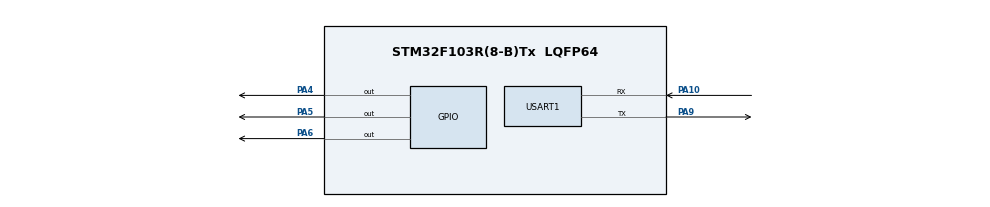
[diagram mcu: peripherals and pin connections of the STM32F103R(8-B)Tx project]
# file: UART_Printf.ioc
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Mcu.Family=STM32F1
Mcu.Name=STM32F103R(8-B)Tx
Mcu.Package=LQFP64
NVIC.PriorityGroup=NVIC_PRIORITYGROUP_2
NVIC.USART1_IRQn=true\:2\:3\:true\:false\:true\:true\:true\:true
PA10.Mode=Asynchronous
PA10.Signal=USART1_RX
PA4.Signal=GPIO_Output
PA5.Signal=GPIO_Output
PA6.Signal=GPIO_Output
PA9.Mode=Asynchronous
PA9.Signal=USART1_TX
ProjectManager.HeapSize=0x200
ProjectManager.StackSize=0x400
ProjectManager.TargetToolchain=CMake
RCC.APB1Freq_Value=8000000
RCC.APB2Freq_Value=8000000
USART1.VirtualMode=VM_ASYNC
VP_SYS_VS_ND.Mode=No_Debug
board=custom

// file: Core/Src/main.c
/* USER CODE BEGIN Header */
/**
  ******************************************************************************
  * @file           : main.c
  * @brief          : Main program body
  ******************************************************************************
  * @attention
  *
  * Copyright (c) 2025 STMicroelectronics.
  * All rights reserved.
  *
  * This software is licensed under terms that can be found in the LICENSE file
  * in the root directory of this software component.
  * If no LICENSE file comes with this software, it is provided AS-IS.
  *
  ******************************************************************************
  */
/* USER CODE END Header */
#include "main.h"
#include "usart.h"
#include "gpio.h"
#include <stdio.h>
#include <string.h>
#include <stdint.h>
#include <stdbool.h>
#include "Unity/unity.h"

/* Test function declarations */
void test_uart_init_should_set_baudrate(void);
void test_uart_transmit_should_return_ok(void);

void SystemClock_Config(void);

/* USER CODE BEGIN 0 */
int __io_putchar(int ch)
{
  HAL_UART_Transmit(&huart1, (uint8_t *)&ch, 1, HAL_MAX_DELAY & 0xFFFF);
  return ch;
}
/* USER CODE END 0 */

int main(void)
{

  /* MCU Configuration--------------------------------------------------------*/

  /* Reset of all peripherals, Initializes the Flash interface and the Systick. */
  HAL_Init();

  /* Configure the system clock */
  SystemClock_Config();

  /* Initialize all configured peripherals */
  MX_GPIO_Init();
  MX_USART1_UART_Init();
  /* USER CODE BEGIN 2 */

  /* Run unit tests */
  printf("\r\n=== Starting UART Tests ===\r\n");
  UNITY_BEGIN();
  RUN_TEST(test_uart_init_should_set_baudrate);
  RUN_TEST(test_uart_transmit_should_return_ok);
  UNITY_END();
  printf("=== UART Tests Complete ===\r\n\r\n");

  /* USER CODE END 2 */

  /* Infinite loop */
  /* USER CODE BEGIN WHILE */
  while (1)
  {
    // static uint8_t cnt = 0;
    /* USER CODE END WHILE */
    // printf("Hello from UART Printf Example %d\r\n", cnt++);
    // HAL_Delay(100);
  }
}

void SystemClock_Config(void)
{
  RCC_OscInitTypeDef RCC_OscInitStruct = {0};
  RCC_ClkInitTypeDef RCC_ClkInitStruct = {0};

  /** Initializes the RCC Oscillators according to the specified parameters
  * in the RCC_OscInitTypeDef structure.
  */
  RCC_OscInitStruct.OscillatorType = RCC_OSCILLATORTYPE_HSI;
  RCC_OscInitStruct.HSIState = RCC_HSI_ON;
  RCC_OscInitStruct.HSICalibrationValue = RCC_HSICALIBRATION_DEFAULT;
  RCC_OscInitStruct.PLL.PLLState = RCC_PLL_NONE;
  if (HAL_RCC_OscConfig(&RCC_OscInitStruct) != HAL_OK)
  {
    Error_Handler();
  }

  /** Initializes the CPU, AHB and APB buses clocks
  */
  RCC_ClkInitStruct.ClockType = RCC_CLOCKTYPE_HCLK|RCC_CLOCKTYPE_SYSCLK
                              |RCC_CLOCKTYPE_PCLK1|RCC_CLOCKTYPE_PCLK2;
  RCC_ClkInitStruct.SYSCLKSource = RCC_SYSCLKSOURCE_HSI;
  RCC_ClkInitStruct.AHBCLKDivider = RCC_SYSCLK_DIV1;
  RCC_ClkInitStruct.APB1CLKDivider = RCC_HCLK_DIV1;
  RCC_ClkInitStruct.APB2CLKDivider = RCC_HCLK_DIV1;

  if (HAL_RCC_ClockConfig(&RCC_ClkInitStruct, FLASH_LATENCY_0) != HAL_OK)
  {
    Error_Handler();
  }
}

void Error_Handler(void)
{
  __disable_irq();
  while (1)
  {
  }
}
